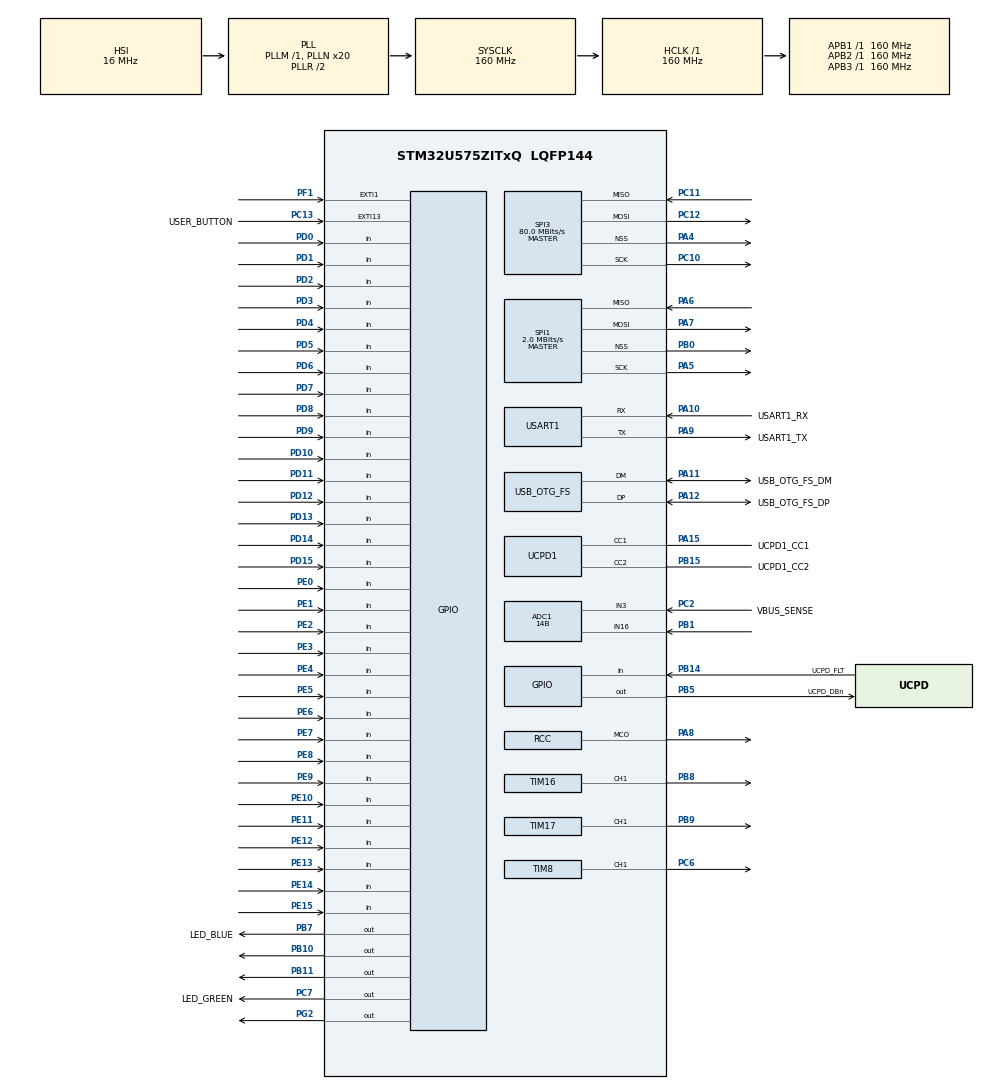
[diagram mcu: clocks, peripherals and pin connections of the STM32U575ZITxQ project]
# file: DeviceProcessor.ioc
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ADC1.ClockPrescaler=ADC_CLOCK_ASYNC_DIV256
ADC1.ContinuousConvMode=ENABLE
ADC1.NbrOfConversion=1
ADC1.Resolution=ADC_RESOLUTION_14B
ADC1.master=1
CORTEX_M33_NS.userName=CORTEX_M33
GPDMA1.DESTDATAWIDTH_GPDMACH12=DMA_DEST_DATAWIDTH_HALFWORD
GPDMA1.DESTINC_GPDMACH12=DMA_DINC_INCREMENTED
GPDMA1.IPHANDLE_GPDMACH12-SIMPLEREQUEST_GPDMACH12=__NULL
GPDMA1.PRIORITY_GPDMACH12=DMA_LOW_PRIORITY_HIGH_WEIGHT
GPDMA1.REQUEST_GPDMACH12=GPDMA1_REQUEST_TIM8_UP
GPDMA1.SRCDATAWIDTH_GPDMACH12=DMA_SRC_DATAWIDTH_HALFWORD
GPDMA1.SRCINC_GPDMACH12=DMA_SINC_FIXED
GPDMA1.TRIGGERPOLARITY_GPDMACH12=DMA_TRIG_POLARITY_MASKED
Mcu.Family=STM32U5
Mcu.Name=STM32U575ZITxQ
Mcu.Package=LQFP144
NVIC.EXTI1_IRQn=true\:0\:0\:false\:false\:true\:true\:true\:true
NVIC.GPDMA1_Channel12_IRQn=true\:0\:0\:false\:false\:true\:false\:true\:true
NVIC.OTG_FS_IRQn=true\:0\:0\:false\:false\:true\:true\:true\:true
NVIC.PriorityGroup=NVIC_PRIORITYGROUP_3
PA10.GPIO_Label=USART1_RX
PA10.GPIO_PuPd=GPIO_PULLDOWN
PA10.GPIO_Speed=GPIO_SPEED_FREQ_VERY_HIGH
PA10.Mode=Asynchronous
PA10.Signal=USART1_RX
PA11.GPIO_Label=USB_OTG_FS_DM
PA11.GPIO_Speed=GPIO_SPEED_FREQ_VERY_HIGH
PA11.Mode=Device_Only
PA11.Signal=USB_OTG_FS_DM
PA12.GPIO_Label=USB_OTG_FS_DP
PA12.GPIO_Speed=GPIO_SPEED_FREQ_VERY_HIGH
PA12.Mode=Device_Only
PA12.Signal=USB_OTG_FS_DP
PA13\ (JTMS/SWDIO).Mode=Trace_Asynchronous_SW
PA13\ (JTMS/SWDIO).Signal=DEBUG_JTMS-SWDIO
PA14\ (JTCK/SWCLK).Mode=Trace_Asynchronous_SW
PA14\ (JTCK/SWCLK).Signal=DEBUG_JTCK-SWCLK
PA15\ (JTDI).GPIO_Label=UCPD1_CC1
PA15\ (JTDI).Mode=Sink_AllSignals
PA15\ (JTDI).Signal=UCPD1_CC1
PA4.Mode=NSS_Signal_Hard_Output
PA4.Signal=SPI3_NSS
PA5.Mode=Full_Duplex_Master
PA5.Signal=SPI1_SCK
PA6.Mode=Full_Duplex_Master
PA6.Signal=SPI1_MISO
PA7.Mode=Full_Duplex_Master
PA7.Signal=SPI1_MOSI
PA8.Mode=Clock-out
PA8.Signal=RCC_MCO
PA9.GPIO_Label=USART1_TX
PA9.GPIO_PuPd=GPIO_PULLDOWN
PA9.GPIO_Speed=GPIO_SPEED_FREQ_VERY_HIGH
PA9.Mode=Asynchronous
PA9.Signal=USART1_TX
PB0.Mode=NSS_Signal_Hard_Output
PB0.Signal=SPI1_NSS
PB1.Mode=IN16-Single-Ended
PB1.Signal=ADC1_IN16
PB10.Signal=GPIO_Output
PB11.Signal=GPIO_Output
PB14.GPIO_Label=UCPD_FLT
PB14.Signal=GPIO_Input
PB15.GPIO_Label=UCPD1_CC2
PB15.Mode=Sink_AllSignals
PB15.Signal=UCPD1_CC2
PB3\ (JTDO/TRACESWO).Mode=Trace_Asynchronous_SW
PB3\ (JTDO/TRACESWO).Signal=DEBUG_JTDO-SWO
PB5.GPIO_Label=UCPD_DBn
PB5.Signal=GPIO_Output
PB7.GPIO_Label=LED_BLUE
PB7.GPIO_ModeDefaultOutputPP=GPIO_MODE_OUTPUT_PP
PB7.GPIO_PuPd=GPIO_PULLUP
PB7.GPIO_Speed=GPIO_SPEED_FREQ_HIGH
PB7.Signal=GPIO_Output
PB8.Signal=S_TIM16_CH1
PB9.Signal=S_TIM17_CH1
PC10.Mode=Full_Duplex_Master
PC10.Signal=SPI3_SCK
PC11.Mode=Full_Duplex_Master
PC11.Signal=SPI3_MISO
PC12.Mode=Full_Duplex_Master
PC12.Signal=SPI3_MOSI
PC13.GPIO_Label=USER_BUTTON
PC13.GPIO_ModeDefaultEXTI=GPIO_MODE_IT_FALLING
PC13.Signal=GPXTI13
PC14-OSC32_IN\ (PC14).Mode=LSE-External-Oscillator
PC14-OSC32_IN\ (PC14).Signal=RCC_OSC32_IN
PC15-OSC32_OUT\ (PC15).Mode=LSE-External-Oscillator
PC15-OSC32_OUT\ (PC15).Signal=RCC_OSC32_OUT
PC2.GPIO_Label=VBUS_SENSE
PC2.Mode=IN3-Single-Ended
PC2.Signal=ADC1_IN3
PC6.GPIO_Speed=GPIO_SPEED_FREQ_VERY_HIGH
PC6.Signal=S_TIM8_CH1
PC7.GPIO_Label=LED_GREEN
PC7.GPIO_PuPd=GPIO_PULLUP
PC7.GPIO_Speed=GPIO_SPEED_FREQ_HIGH
PC7.Signal=GPIO_Output
PD0.Signal=GPIO_Input
PD1.Signal=GPIO_Input
PD10.Signal=GPIO_Input
PD11.Signal=GPIO_Input
PD12.Signal=GPIO_Input
PD13.Signal=GPIO_Input
PD14.Signal=GPIO_Input
PD15.Signal=GPIO_Input
PD2.Signal=GPIO_Input
PD3.Signal=GPIO_Input
PD4.Signal=GPIO_Input
PD5.Signal=GPIO_Input
PD6.Signal=GPIO_Input
PD7.Signal=GPIO_Input
PD8.Signal=GPIO_Input
PD9.Signal=GPIO_Input
PE0.Signal=GPIO_Input
PE1.Signal=GPIO_Input
PE10.Signal=GPIO_Input
PE11.Signal=GPIO_Input
PE12.Signal=GPIO_Input
PE13.Signal=GPIO_Input
PE14.Signal=GPIO_Input
PE15.Signal=GPIO_Input
PE2.Signal=GPIO_Input
PE3.Signal=GPIO_Input
PE4.Signal=GPIO_Input
PE5.Signal=GPIO_Input
PE6.Signal=GPIO_Input
PE7.Signal=GPIO_Input
PE8.Signal=GPIO_Input
PE9.Signal=GPIO_Input
PF1.Signal=GPXTI1
PG2.Signal=GPIO_Output
PWR.PowerMode=PWR_SMPS_SUPPLY
ProjectManager.HeapSize=0x200
ProjectManager.StackSize=0x400
ProjectManager.TargetToolchain=STM32CubeIDE
RCC.ADCFreq_Value=16000000
RCC.AHBFreq_Value=160000000
RCC.APB1Freq_Value=160000000
RCC.APB1TimFreq_Value=160000000
RCC.APB2Freq_Value=160000000
RCC.APB2TimFreq_Value=160000000
RCC.APB3Freq_Value=160000000
RCC.CortexFreq_Value=160000000
RCC.DACCLockSelectionVirtual=RCC_DAC1CLKSOURCE_LSI
RCC.EPOD_VALUE=16000000
RCC.HCLKFreq_Value=160000000
RCC.HSE_VALUE=16000000
RCC.HSI48_VALUE=48000000
RCC.HSI_VALUE=16000000
RCC.LSIDIV_VALUE=32000
RCC.MSI_VALUE=4000000
RCC.PLL2N=20
RCC.PLL2Source=RCC_PLLSOURCE_HSI
RCC.PLLN=20
RCC.PLLSourceVirtual=RCC_PLLSOURCE_HSI
RCC.RCC_MCODiv=RCC_MCODIV_8
RCC.SPI1CLockSelection=RCC_SPI1CLKSOURCE_MSIK
RCC.SYSCLKFreq_VALUE=160000000
RCC.SYSCLKSource=RCC_SYSCLKSOURCE_PLLCLK
RCC.USBFreq_Value=48000000
RCC.VCOOutputFreq_Value=320000000
SH.S_TIM16_CH1.0=TIM16_CH1,Output Compare1 CH1
SH.S_TIM17_CH1.0=TIM17_CH1,PWM Generation1 CH1
SH.S_TIM8_CH1.0=TIM8_CH1,Output Compare1 CH1
SPI1.CLKPolarity=SPI_POLARITY_HIGH
SPI1.CalculateBaudRate=2.0 MBits/s
SPI1.DataSize=SPI_DATASIZE_8BIT
SPI1.Direction=SPI_DIRECTION_2LINES
SPI1.Mode=SPI_MODE_MASTER
SPI1.VirtualNSS=VM_NSSHARD
SPI1.VirtualType=VM_MASTER
SPI3.CalculateBaudRate=80.0 MBits/s
SPI3.Direction=SPI_DIRECTION_2LINES
SPI3.Mode=SPI_MODE_MASTER
SPI3.VirtualNSS=VM_NSSHARD
SPI3.VirtualType=VM_MASTER
TIM15.AutoReloadPreload=TIM_AUTORELOAD_PRELOAD_ENABLE
TIM16.AutoReloadPreload=TIM_AUTORELOAD_PRELOAD_ENABLE
TIM16.Channel=TIM_CHANNEL_1
TIM17.AutoReloadPreload=TIM_AUTORELOAD_PRELOAD_ENABLE
TIM17.Channel=TIM_CHANNEL_1
TIM8.AutoReloadPreload=TIM_AUTORELOAD_PRELOAD_ENABLE
TIM8.Channel-Output\ Compare1\ CH1=TIM_CHANNEL_1
TIM8.OC1Preload=ENABLE
TIM8.OCMode_1=TIM_OCMODE_TOGGLE
TIM8.PulseNoDither_1=4/2
USART1.VirtualMode-Asynchronous=VM_ASYNC
USB_OTG_FS.VirtualMode=Device_Only
VP_FLASH_SIG_Activate_FlashIP.Mode=Activate_FlashIP
VP_GPDMA1_VS_GPDMACH12.Mode=SIMPLEREQUEST_GPDMACH12
VP_ICACHE_VS_ENABLE_ICACHE_MEMORY.Mode=Memoryregions
VP_ICACHE_VS_ICACHE.Mode=DirectMappedCache
VP_LPBAMQUEUE_VS_QUEUE.Mode=QUEUEMODE
VP_LPBAM_VS_SIG1.Mode=SmartRun
VP_LPBAM_VS_SIG4.Mode=LPDMA1
VP_MEMORYMAP_VS_MEMORYMAP.Mode=CurAppReg
VP_PWR_VS_DBSignals.Mode=DisableDeadBatterySignals
VP_PWR_VS_LPOM.Mode=PowerOptimisation
VP_PWR_VS_SECSignals.Mode=Security/Privilege
VP_PWR_Vdda.Mode=isolationVdda
VP_TIM15_VS_ClockSourceINT.Mode=Internal
VP_TIM16_VS_ClockSourceINT.Mode=Enable_Timer
VP_TIM17_VS_ClockSourceINT.Mode=Enable_Timer
VP_TIM8_VS_ClockSourceINT.Mode=Internal
board=NUCLEO-U575ZI-Q

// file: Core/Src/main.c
/* USER CODE BEGIN Header */
/**
  ******************************************************************************
  * @file           : main.c
  * @brief          : Main program body
  ******************************************************************************
  * @attention
  *
  * Copyright (c) 2024 STMicroelectronics.
  * All rights reserved.
  *
  * This software is licensed under terms that can be found in the LICENSE file
  * in the root directory of this software component.
  * If no LICENSE file comes with this software, it is provided AS-IS.
  *
  ******************************************************************************
  */
/* USER CODE END Header */
#include "main.h"

ADC_HandleTypeDef hadc1;

SPI_HandleTypeDef hspi1;
SPI_HandleTypeDef hspi3;

TIM_HandleTypeDef htim8;
TIM_HandleTypeDef htim15;
TIM_HandleTypeDef htim16;
TIM_HandleTypeDef htim17;
DMA_HandleTypeDef handle_GPDMA1_Channel12;

UART_HandleTypeDef huart1;

PCD_HandleTypeDef hpcd_USB_OTG_FS;

/* USER CODE BEGIN PV */
uint8_t spiTxBufferTest[] = {0x21,0x00,0x50,0xC7,0x40,0x00,0xC0,0x00,0x20,0x00};
/* USER CODE END PV */

void SystemClock_Config(void);
static void SystemPower_Config(void);
static void MX_GPIO_Init(void);
static void MX_GPDMA1_Init(void);
static void MX_ADC1_Init(void);
static void MX_ICACHE_Init(void);
static void MX_UCPD1_Init(void);
static void MX_USART1_UART_Init(void);
static void MX_SPI1_Init(void);
static void MX_FLASH_Init(void);
static void MX_USB_OTG_FS_PCD_Init(void);
static void MX_TIM15_Init(void);
static void MX_TIM16_Init(void);
static void MX_TIM17_Init(void);
static void MX_TIM8_Init(void);
static void MX_SPI3_Init(void);

int main(void)
{

  /* MCU Configuration--------------------------------------------------------*/

  /* Reset of all peripherals, Initializes the Flash interface and the Systick. */
  HAL_Init();

  /* Configure the System Power */
  SystemPower_Config();

  /* Configure the system clock */
  SystemClock_Config();

  /* Initialize all configured peripherals */
  MX_GPIO_Init();
  MX_GPDMA1_Init();
  MX_ADC1_Init();
  MX_ICACHE_Init();
  MX_UCPD1_Init();
  MX_USART1_UART_Init();
  MX_SPI1_Init();
  MX_FLASH_Init();
  MX_USB_OTG_FS_PCD_Init();
  MX_TIM15_Init();
  MX_TIM16_Init();
  MX_TIM17_Init();
  MX_TIM8_Init();
  MX_SPI3_Init();
  /* USER CODE BEGIN 2 */
  //HAL_SPI_Transmit(&hspi1, spiTxBuffer1, 10, 1000);
  //HAL_DELAY(3000);
  run_device();
  /* USER CODE END 2 */

  /* Infinite loop */
  while (1)
  {

  }
}

void SystemClock_Config(void)
{
  RCC_OscInitTypeDef RCC_OscInitStruct = {0};
  RCC_ClkInitTypeDef RCC_ClkInitStruct = {0};

  /** Configure the main internal regulator output voltage
  */
  if (HAL_PWREx_ControlVoltageScaling(PWR_REGULATOR_VOLTAGE_SCALE1) != HAL_OK)
  {
    Error_Handler();
  }

  /** Initializes the CPU, AHB and APB buses clocks
  */
  RCC_OscInitStruct.OscillatorType = RCC_OSCILLATORTYPE_HSI48|RCC_OSCILLATORTYPE_HSI
                              |RCC_OSCILLATORTYPE_MSIK;
  RCC_OscInitStruct.HSIState = RCC_HSI_ON;
  RCC_OscInitStruct.HSI48State = RCC_HSI48_ON;
  RCC_OscInitStruct.HSICalibrationValue = RCC_HSICALIBRATION_DEFAULT;
  RCC_OscInitStruct.MSICalibrationValue = RCC_MSICALIBRATION_DEFAULT;
  RCC_OscInitStruct.MSIKClockRange = RCC_MSIKRANGE_4;
  RCC_OscInitStruct.MSIKState = RCC_MSIK_ON;
  RCC_OscInitStruct.PLL.PLLState = RCC_PLL_ON;
  RCC_OscInitStruct.PLL.PLLSource = RCC_PLLSOURCE_HSI;
  RCC_OscInitStruct.PLL.PLLMBOOST = RCC_PLLMBOOST_DIV1;
  RCC_OscInitStruct.PLL.PLLM = 1;
  RCC_OscInitStruct.PLL.PLLN = 20;
  RCC_OscInitStruct.PLL.PLLP = 2;
  RCC_OscInitStruct.PLL.PLLQ = 2;
  RCC_OscInitStruct.PLL.PLLR = 2;
  RCC_OscInitStruct.PLL.PLLRGE = RCC_PLLVCIRANGE_1;
  RCC_OscInitStruct.PLL.PLLFRACN = 0;
  if (HAL_RCC_OscConfig(&RCC_OscInitStruct) != HAL_OK)
  {
    Error_Handler();
  }

  /** Initializes the CPU, AHB and APB buses clocks
  */
  RCC_ClkInitStruct.ClockType = RCC_CLOCKTYPE_HCLK|RCC_CLOCKTYPE_SYSCLK
                              |RCC_CLOCKTYPE_PCLK1|RCC_CLOCKTYPE_PCLK2
                              |RCC_CLOCKTYPE_PCLK3;
  RCC_ClkInitStruct.SYSCLKSource = RCC_SYSCLKSOURCE_PLLCLK;
  RCC_ClkInitStruct.AHBCLKDivider = RCC_SYSCLK_DIV1;
  RCC_ClkInitStruct.APB1CLKDivider = RCC_HCLK_DIV1;
  RCC_ClkInitStruct.APB2CLKDivider = RCC_HCLK_DIV1;
  RCC_ClkInitStruct.APB3CLKDivider = RCC_HCLK_DIV1;

  if (HAL_RCC_ClockConfig(&RCC_ClkInitStruct, FLASH_LATENCY_4) != HAL_OK)
  {
    Error_Handler();
  }

  /** MCO configuration
  */
  HAL_RCC_MCOConfig(RCC_MCO1, RCC_MCO1SOURCE_SYSCLK, RCC_MCODIV_8);
}

/**
  * @brief Power Configuration
  * @retval None
  */
static void SystemPower_Config(void)
{
  HAL_PWREx_EnableVddIO2();

  /*
   * Switch to SMPS regulator instead of LDO
   */
  if (HAL_PWREx_ConfigSupply(PWR_SMPS_SUPPLY) != HAL_OK)
  {
    Error_Handler();
  }
}

static void MX_ADC1_Init(void)
{

  /** Common config
  */
  hadc1.Instance = ADC1;
  hadc1.Init.ClockPrescaler = ADC_CLOCK_ASYNC_DIV256;
  hadc1.Init.Resolution = ADC_RESOLUTION_14B;
  hadc1.Init.GainCompensation = 0;
  hadc1.Init.ScanConvMode = ADC_SCAN_DISABLE;
  hadc1.Init.EOCSelection = ADC_EOC_SINGLE_CONV;
  hadc1.Init.LowPowerAutoWait = DISABLE;
  hadc1.Init.ContinuousConvMode = ENABLE;
  hadc1.Init.NbrOfConversion = 1;
  hadc1.Init.DiscontinuousConvMode = DISABLE;
  hadc1.Init.DMAContinuousRequests = DISABLE;
  hadc1.Init.TriggerFrequencyMode = ADC_TRIGGER_FREQ_HIGH;
  hadc1.Init.Overrun = ADC_OVR_DATA_PRESERVED;
  hadc1.Init.LeftBitShift = ADC_LEFTBITSHIFT_NONE;
  hadc1.Init.ConversionDataManagement = ADC_CONVERSIONDATA_DR;
  hadc1.Init.OversamplingMode = DISABLE;
  if (HAL_ADC_Init(&hadc1) != HAL_OK)
  {
    Error_Handler();
  }

}

static void MX_FLASH_Init(void)
{

  if (HAL_FLASH_Unlock() != HAL_OK)
  {
    Error_Handler();
  }
  if (HAL_FLASH_Lock() != HAL_OK)
  {
    Error_Handler();
  }

}

static void MX_GPDMA1_Init(void)
{

  /* Peripheral clock enable */
  __HAL_RCC_GPDMA1_CLK_ENABLE();

  /* GPDMA1 interrupt Init */
    HAL_NVIC_SetPriority(GPDMA1_Channel12_IRQn, 0, 0);
    HAL_NVIC_EnableIRQ(GPDMA1_Channel12_IRQn);

}

static void MX_ICACHE_Init(void)
{

  /** Enable instruction cache in 1-way (direct mapped cache)
  */
  if (HAL_ICACHE_ConfigAssociativityMode(ICACHE_1WAY) != HAL_OK)
  {
    Error_Handler();
  }
  if (HAL_ICACHE_Enable() != HAL_OK)
  {
    Error_Handler();
  }

}

static void MX_SPI1_Init(void)
{

  SPI_AutonomousModeConfTypeDef HAL_SPI_AutonomousMode_Cfg_Struct = {0};

  /* SPI1 parameter configuration*/
  hspi1.Instance = SPI1;
  hspi1.Init.Mode = SPI_MODE_MASTER;
  hspi1.Init.Direction = SPI_DIRECTION_2LINES;
  hspi1.Init.DataSize = SPI_DATASIZE_8BIT;
  hspi1.Init.CLKPolarity = SPI_POLARITY_HIGH;
  hspi1.Init.CLKPhase = SPI_PHASE_1EDGE;
  hspi1.Init.NSS = SPI_NSS_HARD_OUTPUT;
  hspi1.Init.BaudRatePrescaler = SPI_BAUDRATEPRESCALER_2;
  hspi1.Init.FirstBit = SPI_FIRSTBIT_MSB;
  hspi1.Init.TIMode = SPI_TIMODE_DISABLE;
  hspi1.Init.CRCCalculation = SPI_CRCCALCULATION_DISABLE;
  hspi1.Init.CRCPolynomial = 0x7;
  hspi1.Init.NSSPMode = SPI_NSS_PULSE_ENABLE;
  hspi1.Init.NSSPolarity = SPI_NSS_POLARITY_LOW;
  hspi1.Init.FifoThreshold = SPI_FIFO_THRESHOLD_01DATA;
  hspi1.Init.MasterSSIdleness = SPI_MASTER_SS_IDLENESS_00CYCLE;
  hspi1.Init.MasterInterDataIdleness = SPI_MASTER_INTERDATA_IDLENESS_00CYCLE;
  hspi1.Init.MasterReceiverAutoSusp = SPI_MASTER_RX_AUTOSUSP_DISABLE;
  hspi1.Init.MasterKeepIOState = SPI_MASTER_KEEP_IO_STATE_DISABLE;
  hspi1.Init.IOSwap = SPI_IO_SWAP_DISABLE;
  hspi1.Init.ReadyMasterManagement = SPI_RDY_MASTER_MANAGEMENT_INTERNALLY;
  hspi1.Init.ReadyPolarity = SPI_RDY_POLARITY_HIGH;
  if (HAL_SPI_Init(&hspi1) != HAL_OK)
  {
    Error_Handler();
  }
  HAL_SPI_AutonomousMode_Cfg_Struct.TriggerState = SPI_AUTO_MODE_DISABLE;
  HAL_SPI_AutonomousMode_Cfg_Struct.TriggerSelection = SPI_GRP1_GPDMA_CH0_TCF_TRG;
  HAL_SPI_AutonomousMode_Cfg_Struct.TriggerPolarity = SPI_TRIG_POLARITY_RISING;
  if (HAL_SPIEx_SetConfigAutonomousMode(&hspi1, &HAL_SPI_AutonomousMode_Cfg_Struct) != HAL_OK)
  {
    Error_Handler();
  }

}

static void MX_SPI3_Init(void)
{

  SPI_AutonomousModeConfTypeDef HAL_SPI_AutonomousMode_Cfg_Struct = {0};

  /* SPI3 parameter configuration*/
  hspi3.Instance = SPI3;
  hspi3.Init.Mode = SPI_MODE_MASTER;
  hspi3.Init.Direction = SPI_DIRECTION_2LINES;
  hspi3.Init.DataSize = SPI_DATASIZE_8BIT;
  hspi3.Init.CLKPolarity = SPI_POLARITY_LOW;
  hspi3.Init.CLKPhase = SPI_PHASE_1EDGE;
  hspi3.Init.NSS = SPI_NSS_HARD_OUTPUT;
  hspi3.Init.BaudRatePrescaler = SPI_BAUDRATEPRESCALER_2;
  hspi3.Init.FirstBit = SPI_FIRSTBIT_MSB;
  hspi3.Init.TIMode = SPI_TIMODE_DISABLE;
  hspi3.Init.CRCCalculation = SPI_CRCCALCULATION_DISABLE;
  hspi3.Init.CRCPolynomial = 0x7;
  hspi3.Init.NSSPMode = SPI_NSS_PULSE_ENABLE;
  hspi3.Init.NSSPolarity = SPI_NSS_POLARITY_LOW;
  hspi3.Init.FifoThreshold = SPI_FIFO_THRESHOLD_01DATA;
  hspi3.Init.MasterSSIdleness = SPI_MASTER_SS_IDLENESS_00CYCLE;
  hspi3.Init.MasterInterDataIdleness = SPI_MASTER_INTERDATA_IDLENESS_00CYCLE;
  hspi3.Init.MasterReceiverAutoSusp = SPI_MASTER_RX_AUTOSUSP_DISABLE;
  hspi3.Init.MasterKeepIOState = SPI_MASTER_KEEP_IO_STATE_DISABLE;
  hspi3.Init.IOSwap = SPI_IO_SWAP_DISABLE;
  hspi3.Init.ReadyMasterManagement = SPI_RDY_MASTER_MANAGEMENT_INTERNALLY;
  hspi3.Init.ReadyPolarity = SPI_RDY_POLARITY_HIGH;
  if (HAL_SPI_Init(&hspi3) != HAL_OK)
  {
    Error_Handler();
  }
  HAL_SPI_AutonomousMode_Cfg_Struct.TriggerState = SPI_AUTO_MODE_DISABLE;
  HAL_SPI_AutonomousMode_Cfg_Struct.TriggerSelection = SPI_GRP2_LPDMA_CH0_TCF_TRG;
  HAL_SPI_AutonomousMode_Cfg_Struct.TriggerPolarity = SPI_TRIG_POLARITY_RISING;
  if (HAL_SPIEx_SetConfigAutonomousMode(&hspi3, &HAL_SPI_AutonomousMode_Cfg_Struct) != HAL_OK)
  {
    Error_Handler();
  }

}

static void MX_TIM8_Init(void)
{

  TIM_ClockConfigTypeDef sClockSourceConfig = {0};
  TIM_MasterConfigTypeDef sMasterConfig = {0};
  TIM_OC_InitTypeDef sConfigOC = {0};
  TIM_BreakDeadTimeConfigTypeDef sBreakDeadTimeConfig = {0};

  htim8.Instance = TIM8;
  htim8.Init.Prescaler = 0;
  htim8.Init.CounterMode = TIM_COUNTERMODE_UP;
  htim8.Init.Period = 65535;
  htim8.Init.ClockDivision = TIM_CLOCKDIVISION_DIV1;
  htim8.Init.RepetitionCounter = 0;
  htim8.Init.AutoReloadPreload = TIM_AUTORELOAD_PRELOAD_ENABLE;
  if (HAL_TIM_Base_Init(&htim8) != HAL_OK)
  {
    Error_Handler();
  }
  sClockSourceConfig.ClockSource = TIM_CLOCKSOURCE_INTERNAL;
  if (HAL_TIM_ConfigClockSource(&htim8, &sClockSourceConfig) != HAL_OK)
  {
    Error_Handler();
  }
  if (HAL_TIM_OC_Init(&htim8) != HAL_OK)
  {
    Error_Handler();
  }
  sMasterConfig.MasterOutputTrigger = TIM_TRGO_RESET;
  sMasterConfig.MasterOutputTrigger2 = TIM_TRGO2_RESET;
  sMasterConfig.MasterSlaveMode = TIM_MASTERSLAVEMODE_DISABLE;
  if (HAL_TIMEx_MasterConfigSynchronization(&htim8, &sMasterConfig) != HAL_OK)
  {
    Error_Handler();
  }
  sConfigOC.OCMode = TIM_OCMODE_TOGGLE;
  sConfigOC.Pulse = 2;
  sConfigOC.OCPolarity = TIM_OCPOLARITY_HIGH;
  sConfigOC.OCNPolarity = TIM_OCNPOLARITY_HIGH;
  sConfigOC.OCFastMode = TIM_OCFAST_DISABLE;
  sConfigOC.OCIdleState = TIM_OCIDLESTATE_RESET;
  sConfigOC.OCNIdleState = TIM_OCNIDLESTATE_RESET;
  if (HAL_TIM_OC_ConfigChannel(&htim8, &sConfigOC, TIM_CHANNEL_1) != HAL_OK)
  {
    Error_Handler();
  }
  __HAL_TIM_ENABLE_OCxPRELOAD(&htim8, TIM_CHANNEL_1);
  sBreakDeadTimeConfig.OffStateRunMode = TIM_OSSR_DISABLE;
  sBreakDeadTimeConfig.OffStateIDLEMode = TIM_OSSI_DISABLE;
  sBreakDeadTimeConfig.LockLevel = TIM_LOCKLEVEL_OFF;
  sBreakDeadTimeConfig.DeadTime = 0;
  sBreakDeadTimeConfig.BreakState = TIM_BREAK_DISABLE;
  sBreakDeadTimeConfig.BreakPolarity = TIM_BREAKPOLARITY_HIGH;
  sBreakDeadTimeConfig.BreakFilter = 0;
  sBreakDeadTimeConfig.BreakAFMode = TIM_BREAK_AFMODE_INPUT;
  sBreakDeadTimeConfig.Break2State = TIM_BREAK2_DISABLE;
  sBreakDeadTimeConfig.Break2Polarity = TIM_BREAK2POLARITY_HIGH;
  sBreakDeadTimeConfig.Break2Filter = 0;
  sBreakDeadTimeConfig.Break2AFMode = TIM_BREAK_AFMODE_INPUT;
  sBreakDeadTimeConfig.AutomaticOutput = TIM_AUTOMATICOUTPUT_DISABLE;
  if (HAL_TIMEx_ConfigBreakDeadTime(&htim8, &sBreakDeadTimeConfig) != HAL_OK)
  {
    Error_Handler();
  }
  HAL_TIM_MspPostInit(&htim8);

}

static void MX_TIM15_Init(void)
{

  TIM_ClockConfigTypeDef sClockSourceConfig = {0};
  TIM_MasterConfigTypeDef sMasterConfig = {0};

  htim15.Instance = TIM15;
  htim15.Init.Prescaler = 0;
  htim15.Init.CounterMode = TIM_COUNTERMODE_UP;
  htim15.Init.Period = 65535;
  htim15.Init.ClockDivision = TIM_CLOCKDIVISION_DIV1;
  htim15.Init.RepetitionCounter = 0;
  htim15.Init.AutoReloadPreload = TIM_AUTORELOAD_PRELOAD_ENABLE;
  if (HAL_TIM_Base_Init(&htim15) != HAL_OK)
  {
    Error_Handler();
  }
  sClockSourceConfig.ClockSource = TIM_CLOCKSOURCE_INTERNAL;
  if (HAL_TIM_ConfigClockSource(&htim15, &sClockSourceConfig) != HAL_OK)
  {
    Error_Handler();
  }
  sMasterConfig.MasterOutputTrigger = TIM_TRGO_RESET;
  sMasterConfig.MasterSlaveMode = TIM_MASTERSLAVEMODE_DISABLE;
  if (HAL_TIMEx_MasterConfigSynchronization(&htim15, &sMasterConfig) != HAL_OK)
  {
    Error_Handler();
  }

}

static void MX_TIM16_Init(void)
{

  TIM_OC_InitTypeDef sConfigOC = {0};
  TIM_BreakDeadTimeConfigTypeDef sBreakDeadTimeConfig = {0};

  htim16.Instance = TIM16;
  htim16.Init.Prescaler = 0;
  htim16.Init.CounterMode = TIM_COUNTERMODE_UP;
  htim16.Init.Period = 65535;
  htim16.Init.ClockDivision = TIM_CLOCKDIVISION_DIV1;
  htim16.Init.RepetitionCounter = 0;
  htim16.Init.AutoReloadPreload = TIM_AUTORELOAD_PRELOAD_ENABLE;
  if (HAL_TIM_Base_Init(&htim16) != HAL_OK)
  {
    Error_Handler();
  }
  if (HAL_TIM_OC_Init(&htim16) != HAL_OK)
  {
    Error_Handler();
  }
  sConfigOC.OCMode = TIM_OCMODE_TIMING;
  sConfigOC.Pulse = 0;
  sConfigOC.OCPolarity = TIM_OCPOLARITY_HIGH;
  sConfigOC.OCNPolarity = TIM_OCNPOLARITY_HIGH;
  sConfigOC.OCFastMode = TIM_OCFAST_DISABLE;
  sConfigOC.OCIdleState = TIM_OCIDLESTATE_RESET;
  sConfigOC.OCNIdleState = TIM_OCNIDLESTATE_RESET;
  if (HAL_TIM_OC_ConfigChannel(&htim16, &sConfigOC, TIM_CHANNEL_1) != HAL_OK)
  {
    Error_Handler();
  }
  sBreakDeadTimeConfig.OffStateRunMode = TIM_OSSR_DISABLE;
  sBreakDeadTimeConfig.OffStateIDLEMode = TIM_OSSI_DISABLE;
  sBreakDeadTimeConfig.LockLevel = TIM_LOCKLEVEL_OFF;
  sBreakDeadTimeConfig.DeadTime = 0;
  sBreakDeadTimeConfig.BreakState = TIM_BREAK_DISABLE;
  sBreakDeadTimeConfig.BreakPolarity = TIM_BREAKPOLARITY_HIGH;
  sBreakDeadTimeConfig.BreakFilter = 0;
  sBreakDeadTimeConfig.AutomaticOutput = TIM_AUTOMATICOUTPUT_DISABLE;
  if (HAL_TIMEx_ConfigBreakDeadTime(&htim16, &sBreakDeadTimeConfig) != HAL_OK)
  {
    Error_Handler();
  }
  HAL_TIM_MspPostInit(&htim16);

}

static void MX_TIM17_Init(void)
{

  TIM_OC_InitTypeDef sConfigOC = {0};
  TIM_BreakDeadTimeConfigTypeDef sBreakDeadTimeConfig = {0};

  htim17.Instance = TIM17;
  htim17.Init.Prescaler = 0;
  htim17.Init.CounterMode = TIM_COUNTERMODE_UP;
  htim17.Init.Period = 65535;
  htim17.Init.ClockDivision = TIM_CLOCKDIVISION_DIV1;
  htim17.Init.RepetitionCounter = 0;
  htim17.Init.AutoReloadPreload = TIM_AUTORELOAD_PRELOAD_ENABLE;
  if (HAL_TIM_Base_Init(&htim17) != HAL_OK)
  {
    Error_Handler();
  }
  if (HAL_TIM_PWM_Init(&htim17) != HAL_OK)
  {
    Error_Handler();
  }
  sConfigOC.OCMode = TIM_OCMODE_PWM1;
  sConfigOC.Pulse = 0;
  sConfigOC.OCPolarity = TIM_OCPOLARITY_HIGH;
  sConfigOC.OCNPolarity = TIM_OCNPOLARITY_HIGH;
  sConfigOC.OCFastMode = TIM_OCFAST_DISABLE;
  sConfigOC.OCIdleState = TIM_OCIDLESTATE_RESET;
  sConfigOC.OCNIdleState = TIM_OCNIDLESTATE_RESET;
  if (HAL_TIM_PWM_ConfigChannel(&htim17, &sConfigOC, TIM_CHANNEL_1) != HAL_OK)
  {
    Error_Handler();
  }
  sBreakDeadTimeConfig.OffStateRunMode = TIM_OSSR_DISABLE;
  sBreakDeadTimeConfig.OffStateIDLEMode = TIM_OSSI_DISABLE;
  sBreakDeadTimeConfig.LockLevel = TIM_LOCKLEVEL_OFF;
  sBreakDeadTimeConfig.DeadTime = 0;
  sBreakDeadTimeConfig.BreakState = TIM_BREAK_DISABLE;
  sBreakDeadTimeConfig.BreakPolarity = TIM_BREAKPOLARITY_HIGH;
  sBreakDeadTimeConfig.BreakFilter = 0;
  sBreakDeadTimeConfig.AutomaticOutput = TIM_AUTOMATICOUTPUT_DISABLE;
  if (HAL_TIMEx_ConfigBreakDeadTime(&htim17, &sBreakDeadTimeConfig) != HAL_OK)
  {
    Error_Handler();
  }
  HAL_TIM_MspPostInit(&htim17);

}

static void MX_UCPD1_Init(void)
{

  LL_GPIO_InitTypeDef GPIO_InitStruct = {0};

  /* Peripheral clock enable */
  LL_APB1_GRP2_EnableClock(LL_APB1_GRP2_PERIPH_UCPD1);

  LL_AHB2_GRP1_EnableClock(LL_AHB2_GRP1_PERIPH_GPIOB);
  LL_AHB2_GRP1_EnableClock(LL_AHB2_GRP1_PERIPH_GPIOA);
  /**UCPD1 GPIO Configuration
  PB15   ------> UCPD1_CC2
  PA15 (JTDI)   ------> UCPD1_CC1
  */
  GPIO_InitStruct.Pin = LL_GPIO_PIN_15;
  GPIO_InitStruct.Mode = LL_GPIO_MODE_ANALOG;
  GPIO_InitStruct.Pull = LL_GPIO_PULL_NO;
  LL_GPIO_Init(GPIOB, &GPIO_InitStruct);

  GPIO_InitStruct.Pin = LL_GPIO_PIN_15;
  GPIO_InitStruct.Mode = LL_GPIO_MODE_ANALOG;
  GPIO_InitStruct.Pull = LL_GPIO_PULL_NO;
  LL_GPIO_Init(GPIOA, &GPIO_InitStruct);

}

static void MX_USART1_UART_Init(void)
{

  huart1.Instance = USART1;
  huart1.Init.BaudRate = 115200;
  huart1.Init.WordLength = UART_WORDLENGTH_8B;
  huart1.Init.StopBits = UART_STOPBITS_1;
  huart1.Init.Parity = UART_PARITY_NONE;
  huart1.Init.Mode = UART_MODE_TX_RX;
  huart1.Init.HwFlowCtl = UART_HWCONTROL_NONE;
  huart1.Init.OverSampling = UART_OVERSAMPLING_16;
  huart1.Init.OneBitSampling = UART_ONE_BIT_SAMPLE_DISABLE;
  huart1.Init.ClockPrescaler = UART_PRESCALER_DIV1;
  huart1.AdvancedInit.AdvFeatureInit = UART_ADVFEATURE_NO_INIT;
  if (HAL_UART_Init(&huart1) != HAL_OK)
  {
    Error_Handler();
  }
  if (HAL_UARTEx_SetTxFifoThreshold(&huart1, UART_TXFIFO_THRESHOLD_1_8) != HAL_OK)
  {
    Error_Handler();
  }
  if (HAL_UARTEx_SetRxFifoThreshold(&huart1, UART_RXFIFO_THRESHOLD_1_8) != HAL_OK)
  {
    Error_Handler();
  }
  if (HAL_UARTEx_DisableFifoMode(&huart1) != HAL_OK)
  {
    Error_Handler();
  }

}

static void MX_USB_OTG_FS_PCD_Init(void)
{

  hpcd_USB_OTG_FS.Instance = USB_OTG_FS;
  hpcd_USB_OTG_FS.Init.dev_endpoints = 6;
  hpcd_USB_OTG_FS.Init.speed = PCD_SPEED_FULL;
  hpcd_USB_OTG_FS.Init.phy_itface = PCD_PHY_EMBEDDED;
  hpcd_USB_OTG_FS.Init.Sof_enable = DISABLE;
  hpcd_USB_OTG_FS.Init.low_power_enable = DISABLE;
  hpcd_USB_OTG_FS.Init.lpm_enable = DISABLE;
  hpcd_USB_OTG_FS.Init.battery_charging_enable = DISABLE;
  hpcd_USB_OTG_FS.Init.use_dedicated_ep1 = DISABLE;
  hpcd_USB_OTG_FS.Init.vbus_sensing_enable = DISABLE;
  hpcd_USB_OTG_FS.Init.dma_enable = DISABLE;
  if (HAL_PCD_Init(&hpcd_USB_OTG_FS) != HAL_OK)
  {
    Error_Handler();
  }

}

static void MX_GPIO_Init(void)
{
  GPIO_InitTypeDef GPIO_InitStruct = {0};

  /* GPIO Ports Clock Enable */
  __HAL_RCC_GPIOE_CLK_ENABLE();
  __HAL_RCC_GPIOC_CLK_ENABLE();
  __HAL_RCC_GPIOF_CLK_ENABLE();
  __HAL_RCC_GPIOA_CLK_ENABLE();
  __HAL_RCC_GPIOB_CLK_ENABLE();
  __HAL_RCC_GPIOD_CLK_ENABLE();
  __HAL_RCC_GPIOG_CLK_ENABLE();

  /*Configure GPIO pin Output Level */
  HAL_GPIO_WritePin(GPIOB, GPIO_PIN_10|GPIO_PIN_11|UCPD_DBn_Pin|LED_BLUE_Pin, GPIO_PIN_RESET);

  /*Configure GPIO pin Output Level */
  HAL_GPIO_WritePin(GPIOG, GPIO_PIN_2, GPIO_PIN_RESET);

  /*Configure GPIO pin Output Level */
  HAL_GPIO_WritePin(LED_GREEN_GPIO_Port, LED_GREEN_Pin, GPIO_PIN_RESET);

  /*Configure GPIO pins : PE2 PE3 PE4 PE5
                           PE6 PE7 PE8 PE9
                           PE10 PE11 PE12 PE13
                           PE14 PE15 PE0 PE1 */
  GPIO_InitStruct.Pin = GPIO_PIN_2|GPIO_PIN_3|GPIO_PIN_4|GPIO_PIN_5
                          |GPIO_PIN_6|GPIO_PIN_7|GPIO_PIN_8|GPIO_PIN_9
                          |GPIO_PIN_10|GPIO_PIN_11|GPIO_PIN_12|GPIO_PIN_13
                          |GPIO_PIN_14|GPIO_PIN_15|GPIO_PIN_0|GPIO_PIN_1;
  GPIO_InitStruct.Mode = GPIO_MODE_INPUT;
  GPIO_InitStruct.Pull = GPIO_NOPULL;
  HAL_GPIO_Init(GPIOE, &GPIO_InitStruct);

  /*Configure GPIO pin : USER_BUTTON_Pin */
  GPIO_InitStruct.Pin = USER_BUTTON_Pin;
  GPIO_InitStruct.Mode = GPIO_MODE_IT_FALLING;
  GPIO_InitStruct.Pull = GPIO_NOPULL;
  HAL_GPIO_Init(USER_BUTTON_GPIO_Port, &GPIO_InitStruct);

  /*Configure GPIO pin : PF1 */
  GPIO_InitStruct.Pin = GPIO_PIN_1;
  GPIO_InitStruct.Mode = GPIO_MODE_IT_RISING;
  GPIO_InitStruct.Pull = GPIO_NOPULL;
  HAL_GPIO_Init(GPIOF, &GPIO_InitStruct);

  /*Configure GPIO pins : PB10 PB11 UCPD_DBn_Pin */
  GPIO_InitStruct.Pin = GPIO_PIN_10|GPIO_PIN_11|UCPD_DBn_Pin;
  GPIO_InitStruct.Mode = GPIO_MODE_OUTPUT_PP;
  GPIO_InitStruct.Pull = GPIO_NOPULL;
  GPIO_InitStruct.Speed = GPIO_SPEED_FREQ_LOW;
  HAL_GPIO_Init(GPIOB, &GPIO_InitStruct);

  /*Configure GPIO pin : UCPD_FLT_Pin */
  GPIO_InitStruct.Pin = UCPD_FLT_Pin;
  GPIO_InitStruct.Mode = GPIO_MODE_INPUT;
  GPIO_InitStruct.Pull = GPIO_NOPULL;
  HAL_GPIO_Init(UCPD_FLT_GPIO_Port, &GPIO_InitStruct);

  /*Configure GPIO pins : PD8 PD9 PD10 PD11
                           PD12 PD13 PD14 PD15
                           PD0 PD1 PD2 PD3
                           PD4 PD5 PD6 PD7 */
  GPIO_InitStruct.Pin = GPIO_PIN_8|GPIO_PIN_9|GPIO_PIN_10|GPIO_PIN_11
                          |GPIO_PIN_12|GPIO_PIN_13|GPIO_PIN_14|GPIO_PIN_15
                          |GPIO_PIN_0|GPIO_PIN_1|GPIO_PIN_2|GPIO_PIN_3
                          |GPIO_PIN_4|GPIO_PIN_5|GPIO_PIN_6|GPIO_PIN_7;
  GPIO_InitStruct.Mode = GPIO_MODE_INPUT;
  GPIO_InitStruct.Pull = GPIO_NOPULL;
  HAL_GPIO_Init(GPIOD, &GPIO_InitStruct);

  /*Configure GPIO pin : PG2 */
  GPIO_InitStruct.Pin = GPIO_PIN_2;
  GPIO_InitStruct.Mode = GPIO_MODE_OUTPUT_PP;
  GPIO_InitStruct.Pull = GPIO_NOPULL;
  GPIO_InitStruct.Speed = GPIO_SPEED_FREQ_LOW;
  HAL_GPIO_Init(GPIOG, &GPIO_InitStruct);

  /*Configure GPIO pin : LED_GREEN_Pin */
  GPIO_InitStruct.Pin = LED_GREEN_Pin;
  GPIO_InitStruct.Mode = GPIO_MODE_OUTPUT_PP;
  GPIO_InitStruct.Pull = GPIO_PULLUP;
  GPIO_InitStruct.Speed = GPIO_SPEED_FREQ_HIGH;
  HAL_GPIO_Init(LED_GREEN_GPIO_Port, &GPIO_InitStruct);

  /*Configure GPIO pin : PA8 */
  GPIO_InitStruct.Pin = GPIO_PIN_8;
  GPIO_InitStruct.Mode = GPIO_MODE_AF_PP;
  GPIO_InitStruct.Pull = GPIO_NOPULL;
  GPIO_InitStruct.Speed = GPIO_SPEED_FREQ_HIGH;
  GPIO_InitStruct.Alternate = GPIO_AF0_MCO;
  HAL_GPIO_Init(GPIOA, &GPIO_InitStruct);

  /*Configure GPIO pin : LED_BLUE_Pin */
  GPIO_InitStruct.Pin = LED_BLUE_Pin;
  GPIO_InitStruct.Mode = GPIO_MODE_OUTPUT_PP;
  GPIO_InitStruct.Pull = GPIO_PULLUP;
  GPIO_InitStruct.Speed = GPIO_SPEED_FREQ_HIGH;
  HAL_GPIO_Init(LED_BLUE_GPIO_Port, &GPIO_InitStruct);

  /* EXTI interrupt init*/
  HAL_NVIC_SetPriority(EXTI1_IRQn, 0, 0);
  HAL_NVIC_EnableIRQ(EXTI1_IRQn);

}

void Error_Handler(void)
{
  __disable_irq();
  while (1)
  {
  }
}
